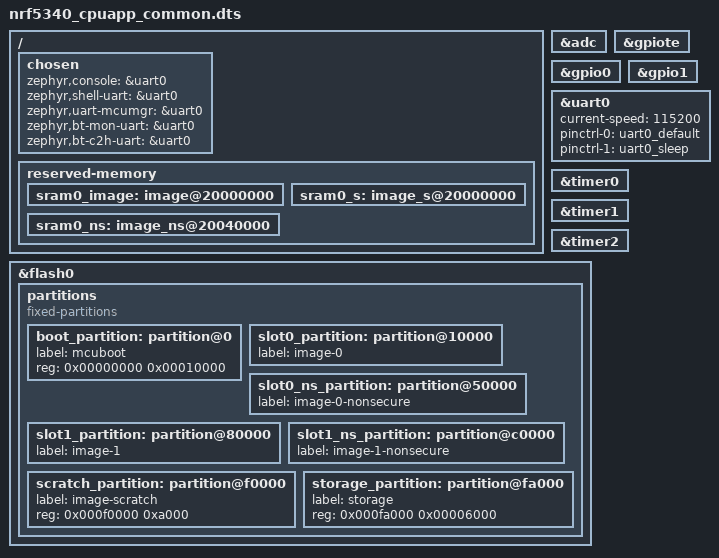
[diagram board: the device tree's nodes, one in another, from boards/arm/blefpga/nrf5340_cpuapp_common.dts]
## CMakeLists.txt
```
#
# Copyright (c) 2018 Nordic Semiconductor
#
# SPDX-License-Identifier: LicenseRef-Nordic-5-Clause
#
cmake_minimum_required(VERSION 3.20.0)

find_package(Zephyr REQUIRED HINTS $ENV{ZEPHYR_BASE})
project(peripheral_uart_app080724d)

# NORDIC SDK APP START
target_sources(app PRIVATE
  src/main.c
  src/utils.c
  src/spimflash.c
)

# Include UART ASYNC API adapter
target_sources_ifdef(CONFIG_BT_NUS_UART_ASYNC_ADAPTER app PRIVATE
  src/uart_async_adapter.c
)

# NORDIC SDK APP END

zephyr_library_include_directories(.)
```

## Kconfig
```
#
# Copyright (c) 2018 Nordic Semiconductor
#
# SPDX-License-Identifier: LicenseRef-Nordic-5-Clause
#

config USB_DEVICE_PID
	default USB_PID_CDC_ACM_SAMPLE

source "Kconfig.zephyr"

menu "Nordic UART BLE GATT service sample"

config BT_NUS_THREAD_STACK_SIZE
	int "Thread stack size"
	default 1024
	help
	  Stack size used in each of the two threads

config BT_NUS_UART_BUFFER_SIZE
	int "UART payload buffer element size"
	default 40
	help
	  Size of the payload buffer in each RX and TX FIFO element

config BT_NUS_SECURITY_ENABLED
	bool "Enable security"
	default y
	select BT_SMP
	help
	  "Enable BLE security for the UART service"

config BT_NUS_UART_RX_WAIT_TIME
	int "Timeout for UART RX complete event"
	default 50
	help
	  Wait for RX complete event time in milliseconds

config BT_NUS_UART_ASYNC_ADAPTER
	bool "Enable UART async adapter"
	select SERIAL_SUPPORT_ASYNC
	help
	  Enables asynchronous adapter for UART drives that supports only
	  IRQ interface.

endmenu
```

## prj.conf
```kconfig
#
# Copyright (c) 2018 Nordic Semiconductor
#
# SPDX-License-Identifier: LicenseRef-Nordic-5-Clause
#

# Enable the UART driver
CONFIG_UART_ASYNC_API=y
CONFIG_NRFX_UARTE0=y
CONFIG_SERIAL=y

CONFIG_GPIO=y

# Make sure printk is printing to the UART console
CONFIG_CONSOLE=y
CONFIG_UART_CONSOLE=y

CONFIG_HEAP_MEM_POOL_SIZE=2048

CONFIG_BT=y
CONFIG_BT_PERIPHERAL=y
CONFIG_BT_DEVICE_NAME="NRFICE"
CONFIG_BT_DEVICE_APPEARANCE=833
CONFIG_BT_MAX_CONN=1
CONFIG_BT_MAX_PAIRED=1

# Enable the NUS service
CONFIG_BT_NUS=y

# Enable bonding
CONFIG_BT_SETTINGS=y
CONFIG_FLASH=y
CONFIG_FLASH_PAGE_LAYOUT=y
CONFIG_FLASH_MAP=y
CONFIG_NVS=y
CONFIG_SETTINGS=y

# Enable DK LED and Buttons library
CONFIG_DK_LIBRARY=y

# This example requires more stack
CONFIG_MAIN_STACK_SIZE=1152
CONFIG_SYSTEM_WORKQUEUE_STACK_SIZE=2048

# Config logger
CONFIG_LOG=y
CONFIG_USE_SEGGER_RTT=y
CONFIG_LOG_BACKEND_RTT=y
CONFIG_LOG_BACKEND_UART=n
CONFIG_LOG_PRINTK=n

CONFIG_ASSERT=y





CONFIG_BT_USER_DATA_LEN_UPDATE=y
CONFIG_BT_USER_PHY_UPDATE=y
CONFIG_BT_GAP_AUTO_UPDATE_CONN_PARAMS=n

CONFIG_BT_BUF_ACL_RX_SIZE=251
CONFIG_BT_GATT_CLIENT=y
CONFIG_BT_ATT_PREPARE_COUNT=2
CONFIG_BT_CONN_TX_MAX=10
CONFIG_BT_L2CAP_TX_BUF_COUNT=10
CONFIG_BT_L2CAP_TX_MTU=247
CONFIG_BT_L2CAP_DYNAMIC_CHANNEL=y
CONFIG_BT_CTLR_PHY_2M=y
CONFIG_BT_CTLR_RX_BUFFERS=2
CONFIG_BT_BUF_ACL_TX_COUNT=10
CONFIG_BT_BUF_ACL_TX_SIZE=251
CONFIG_BT_CTLR_DATA_LENGTH_MAX=251
```

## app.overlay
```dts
/*
 * Copyright (c) 2022 Nordic Semiconductor ASA
 *
 * SPDX-License-Identifier: LicenseRef-Nordic-5-Clause
 */

/ {
	chosen {
		nordic,nus-uart = &uart0;
	};
};

&qspi {
	status = "disabled";
};

&adc {
	status = "disabled";
};
```

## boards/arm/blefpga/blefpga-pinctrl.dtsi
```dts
/*
 * Copyright (c) 2022 Nordic Semiconductor
 * SPDX-License-Identifier: Apache-2.0
 */

&pinctrl {
	/*spi2_default: spi2_default {
		group1 {
			psels = <NRF_PSEL(SPIM_SCK, 1, 15)>,
				<NRF_PSEL(SPIM_MISO, 1, 14)>,
				<NRF_PSEL(SPIM_MOSI, 1, 13)>;
		};
	};

	spi2_sleep: spi2_sleep {
		group1 {
			psels = <NRF_PSEL(SPIM_SCK, 1, 15)>,
				<NRF_PSEL(SPIM_MISO, 1, 14)>,
				<NRF_PSEL(SPIM_MOSI, 1, 13)>;
			low-power-enable;
		};
	};*/

};
```

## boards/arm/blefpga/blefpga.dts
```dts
/*
 * Copyright (c) 2020 Nordic Semiconductor ASA
 *
 * SPDX-License-Identifier: Apache-2.0
 */

/dts-v1/;
#include <nordic/nrf5340_cpuapp_qkaa.dtsi>
#include "nrf5340_cpuapp_common.dts"
#include "blefpga-pinctrl.dtsi"

/ {
	model = "BLEFPGA Application";
	compatible = "nordic,blefpga";

	chosen {
		zephyr,sram = &sram0_image;
		zephyr,flash = &flash0;
		zephyr,code-partition = &slot0_partition;
		zephyr,sram-secure-partition = &sram0_s;
		zephyr,sram-non-secure-partition = &sram0_ns;
	};
};

/*&spi2 {
	compatible = "nordic,nrf-spim";
	status = "okay";
	pinctrl-0 = <&spi2_default>;
	pinctrl-1 = <&spi2_sleep>;
	pinctrl-names = "default", "sleep";
};*/

zephyr_udc0: &usbd {
	compatible = "nordic,nrf-usbd";
	status = "okay";
};
```

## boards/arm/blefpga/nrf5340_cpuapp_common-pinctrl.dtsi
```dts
/*
 * Copyright (c) 2022 Nordic Semiconductor
 * SPDX-License-Identifier: Apache-2.0
 */

&pinctrl {
	/*i2c1_default: i2c1_default {
		group1 {
			psels = <NRF_PSEL(TWIM_SDA, 1, 2)>,
				<NRF_PSEL(TWIM_SCL, 1, 3)>;
		};
	};

	i2c1_sleep: i2c1_sleep {
		group1 {
			psels = <NRF_PSEL(TWIM_SDA, 1, 2)>,
				<NRF_PSEL(TWIM_SCL, 1, 3)>;
			low-power-enable;
		};
	};*/
	uart0_default: uart0_default {
		group1 {
			psels = <NRF_PSEL(UART_TX, 0, 22)>,   //orig: 20, pololu: 26
				<NRF_PSEL(UART_RTS, 0, 30)>;    //orig: 19, pololu: 27
		};
		group2 {
			psels = <NRF_PSEL(UART_RX, 0, 29)>,   //orig: 22, pololu: 6
				<NRF_PSEL(UART_CTS, 1, 7)>;   //orig: 21, pololu: 7
			bias-pull-up;
		};
		
	};

	uart0_sleep: uart0_sleep {
		group1 {
			psels = <NRF_PSEL(UART_TX, 0, 22)>,
				<NRF_PSEL(UART_RX, 0, 29)>,
				<NRF_PSEL(UART_RTS, 0, 30)>,
				<NRF_PSEL(UART_CTS, 1, 7)>;
			low-power-enable;
		};
	};
	/* should be good but not working through ob yet
	uart0_default: uart0_default {
		group1 {
			psels = <NRF_PSEL(UART_TX, 0, 29)>,   //orig: 20, pololu: 26
				<NRF_PSEL(UART_RTS, 0, 30)>;    //orig: 19, pololu: 27
		};
		group2 {
			psels = <NRF_PSEL(UART_RX, 0, 22)>,   //orig: 22, pololu: 6
				<NRF_PSEL(UART_CTS, 1, 7)>;   //orig: 21, pololu: 7
			bias-pull-up;
		};
		
	};

	uart0_sleep: uart0_sleep {
		group1 {
			psels = <NRF_PSEL(UART_TX, 0, 29)>,
				<NRF_PSEL(UART_RX, 0, 22)>,
				<NRF_PSEL(UART_RTS, 0, 30)>,
				<NRF_PSEL(UART_CTS, 1, 7)>;
			low-power-enable;
		};
	};*/

	/*pwm0_default: pwm0_default {
		group1 {
			psels = <NRF_PSEL(PWM_OUT0, 0, 28)>;
		};
	};

	pwm0_sleep: pwm0_sleep {
		group1 {
			psels = <NRF_PSEL(PWM_OUT0, 0, 28)>;
			low-power-enable;
		};
	};*/

	/*qspi_default: qspi_default {
		group1 {
			psels = <NRF_PSEL(QSPI_SCK, 0, 17)>,
				<NRF_PSEL(QSPI_IO0, 0, 13)>,
				<NRF_PSEL(QSPI_IO1, 0, 14)>,
				<NRF_PSEL(QSPI_IO2, 0, 15)>,
				<NRF_PSEL(QSPI_IO3, 0, 16)>,
				<NRF_PSEL(QSPI_CSN, 0, 18)>;
		};
	};

	qspi_sleep: qspi_sleep {
		group1 {
			psels = <NRF_PSEL(QSPI_SCK, 0, 17)>,
				<NRF_PSEL(QSPI_IO0, 0, 13)>,
				<NRF_PSEL(QSPI_IO1, 0, 14)>,
				<NRF_PSEL(QSPI_IO2, 0, 15)>,
				<NRF_PSEL(QSPI_IO3, 0, 16)>,
				<NRF_PSEL(QSPI_CSN, 0, 18)>;
			low-power-enable;
		};
	};*/

	/*uart1_default: uart1_default {
		group1 {
			psels = <NRF_PSEL(UART_TX, 1, 1)>;
		};
		group2 {
			psels = <NRF_PSEL(UART_RX, 1, 0)>;
			bias-pull-up;
		};
	};

	uart1_sleep: uart1_sleep {
		group1 {
			psels = <NRF_PSEL(UART_TX, 1, 1)>,
				<NRF_PSEL(UART_RX, 1, 0)>;
			low-power-enable;
		};
	};*/

	/*spi4_default: spi4_default {
		group1 {
			psels = <NRF_PSEL(SPIM_SCK, 1, 15)>,
				<NRF_PSEL(SPIM_MISO, 1, 14)>,
				<NRF_PSEL(SPIM_MOSI, 1, 13)>;
		};
	};

	spi4_sleep: spi4_sleep {
		group1 {
			psels = <NRF_PSEL(SPIM_SCK, 1, 15)>,
				<NRF_PSEL(SPIM_MISO, 1, 14)>,
				<NRF_PSEL(SPIM_MOSI, 1, 13)>;
			low-power-enable;
		};
	};*/

};
```

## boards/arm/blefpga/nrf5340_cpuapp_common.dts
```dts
/*
 * Copyright (c) 2019-2020 Nordic Semiconductor ASA
 *
 * SPDX-License-Identifier: Apache-2.0
 */
#include "nrf5340_cpuapp_common-pinctrl.dtsi"

/ {

	chosen {
		zephyr,console = &uart0;
		zephyr,shell-uart = &uart0;
		zephyr,uart-mcumgr = &uart0;
		zephyr,bt-mon-uart = &uart0;
		zephyr,bt-c2h-uart = &uart0;
	};

 	/*leds {
		compatible = "gpio-leds";
		led0: led_0 {
			gpios = <&gpio1 4 GPIO_ACTIVE_LOW>;
			label = "Green LED 0";
		};
		led1: led_1 {
			gpios = <&gpio1 5 GPIO_ACTIVE_LOW>;
			label = "Green LED 1";
		};
		led2: led_2 {
			gpios = <&gpio0 19 GPIO_ACTIVE_LOW>;
			label = "Green LED 2";
		};
		led3: led_3 {
			gpios = <&gpio0 29 GPIO_ACTIVE_LOW>;
			label = "Green LED 3";
		};
	};*/

	/*pwmleds {
		compatible = "pwm-leds";
		pwm_led0: pwm_led_0 {
			pwms = <&pwm0 0 PWM_MSEC(20) PWM_POLARITY_INVERTED>;
		};
	};*/

	/*buttons {
		compatible = "gpio-keys";
		button0: button_0 {
			gpios = <&gpio0 23 (GPIO_PULL_UP | GPIO_ACTIVE_LOW)>; //dk:23
			label = "Push button 1";
		};
		button1: button_1 {
			gpios = <&gpio0 24 (GPIO_PULL_UP | GPIO_ACTIVE_LOW)>;
			label = "Push button 2";
		};
		button2: button_2 {
			gpios = <&gpio0 8 (GPIO_PULL_UP | GPIO_ACTIVE_LOW)>;
			label = "Push button 3";
		};
		button3: button_3 {
			gpios = <&gpio0 9 (GPIO_PULL_UP | GPIO_ACTIVE_LOW)>;
			label = "Push button 4";
		};
	};*/

	// arduino_header: connector {
	// 	compatible = "arduino-header-r3";
	// 	#gpio-cells = <2>;
	// 	gpio-map-mask = <0xffffffff 0xffffffc0>;
	// 	gpio-map-pass-thru = <0 0x3f>;
	// 	gpio-map = <0 0 &gpio0 4 0>,	/* A0 */
	// 		   <1 0 &gpio0 5 0>,	/* A1 */
	// 		   <2 0 &gpio0 6 0>,	/* A2 */
	// 		   <3 0 &gpio0 7 0>,	/* A3 */
	// 		   <4 0 &gpio0 25 0>,	/* A4 */
	// 		   <5 0 &gpio0 26 0>,	/* A5 */
	// 		   <6 0 &gpio1 0 0>,	/* D0 */
	// 		   <7 0 &gpio1 1 0>,	/* D1 */
	// 		   <8 0 &gpio1 4 0>,	/* D2 */
	// 		   <9 0 &gpio1 5 0>,	/* D3 */
	// 		   <10 0 &gpio1 6 0>,	/* D4 */
	// 		   <11 0 &gpio1 7 0>,	/* D5 */
	// 		   <12 0 &gpio1 8 0>,	/* D6 */
	// 		   <13 0 &gpio1 9 0>,	/* D7 */
	// 		   <14 0 &gpio1 10 0>,	/* D8 */
	// 		   <15 0 &gpio1 11 0>,	/* D9 */
	// 		   <16 0 &gpio1 12 0>,	/* D10 */
	// 		   <17 0 &gpio1 13 0>,	/* D11 */
	// 		   <18 0 &gpio1 14 0>,	/* D12 */
	// 		   <19 0 &gpio1 15 0>,	/* D13 */
	// 		   <20 0 &gpio1 2 0>,	/* D14 */
	// 		   <21 0 &gpio1 3 0>;	/* D15 */
	// };

 	// arduino_adc: analog-connector {
	// 	compatible = "arduino,uno-adc";
	// 	#io-channel-cells = <1>;
	// 	io-channel-map = <0 &adc 0>,	/* A0 = P0.4 = AIN0 */
	// 			 <1 &adc 1>,	/* A1 = P0.5 = AIN1 */
	// 			 <2 &adc 2>,	/* A2 = P0.6 = AIN2 */
	// 			 <3 &adc 3>,	/* A3 = P0.7 = AIN3 */
	// 			 <4 &adc 4>,	/* A4 = P0.25 = AIN4 */
	// 			 <5 &adc 5>;	/* A5 = P0.26 = AIN5 */
	// };

	/*gpio_fwd: nrf-gpio-forwarder {
		compatible = "nordic,nrf-gpio-forwarder";
		status = "okay";
		uart {
			gpios = <&gpio1 1 0>, <&gpio1 0 0>, <&gpio0 11 0>, <&gpio0 10 0>;
		};
	};*/

	/* These aliases are provided for compatibility with samples */
	/*aliases {
		led0 = &led0;
		led1 = &led1;
		led2 = &led2;
		// led3 = &led3;
		//pwm-led0 = &pwm_led0;
		sw0 = &button0;
		sw1 = &button1;
		sw2 = &button2;
		sw3 = &button3;
		bootloader-led0 = &led0;
	};*/
};

&adc {
	status = "okay";
};

&gpiote {
	status = "okay";
};

&gpio0 {
	status = "okay";
};

&gpio1 {
	status = "okay";
};

/*&i2c1 {
	compatible = "nordic,nrf-twim";
	status = "okay";
	pinctrl-0 = <&i2c1_default>;
	pinctrl-1 = <&i2c1_sleep>;
	pinctrl-names = "default", "sleep";
};*/

&uart0 {
	status = "okay";
	current-speed = <115200>;
	pinctrl-0 = <&uart0_default>;
	pinctrl-1 = <&uart0_sleep>;
	pinctrl-names = "default", "sleep";
	//hw-flow-control;
};

/*&pwm0 {
	status = "okay";
	pinctrl-0 = <&pwm0_default>;
	pinctrl-1 = <&pwm0_sleep>;
	pinctrl-names = "default", "sleep";
};*/

/*&qspi {
	status = "okay";
	pinctrl-0 = <&qspi_default>;
	pinctrl-1 = <&qspi_sleep>;
	pinctrl-names = "default", "sleep";
	mx25r64: mx25r6435f@0 {
		compatible = "nordic,qspi-nor";
		reg = <0>;
		
		writeoc = "pp4io";
		
		readoc = "read4io";
		sck-frequency = <8000000>;
		label = "MX25R64";
		jedec-id = [c2 28 17];
		sfdp-bfp = [
			e5 20 f1 ff  ff ff ff 03  44 eb 08 6b  08 3b 04 bb
			ee ff ff ff  ff ff 00 ff  ff ff 00 ff  0c 20 0f 52
			10 d8 00 ff  23 72 f5 00  82 ed 04 cc  44 83 68 44
			30 b0 30 b0  f7 c4 d5 5c  00 be 29 ff  f0 d0 ff ff
		];
		size = <67108864>;
		has-dpd;
		t-enter-dpd = <10000>;
		t-exit-dpd = <35000>;
	};
};*/

&timer0 {
	status = "okay";
};

&timer1 {
	status = "okay";
};

&timer2 {
	status = "okay";
};

/*arduino_serial: &uart1 {
	compatible = "nordic,nrf-uarte";
	current-speed = <115200>;
	pinctrl-0 = <&uart1_default>;
	pinctrl-1 = <&uart1_sleep>;
	pinctrl-names = "default", "sleep";
};*/

/*arduino_i2c: &i2c1 {};

arduino_spi: &spi4 {
	compatible = "nordic,nrf-spim";
	cs-gpios = <&arduino_header 16 GPIO_ACTIVE_LOW>; 
	pinctrl-0 = <&spi4_default>;
	pinctrl-1 = <&spi4_sleep>;
	pinctrl-names = "default", "sleep";
};*/

&flash0 {

	partitions {
		compatible = "fixed-partitions";
		#address-cells = <1>;
		#size-cells = <1>;

		boot_partition: partition@0 {
			label = "mcuboot";
			reg = <0x00000000 0x00010000>;
		};
		slot0_partition: partition@10000 {
			label = "image-0";
		};
		slot0_ns_partition: partition@50000 {
			label = "image-0-nonsecure";
		};
		slot1_partition: partition@80000 {
			label = "image-1";
		};
		slot1_ns_partition: partition@c0000 {
			label = "image-1-nonsecure";
		};
		scratch_partition: partition@f0000 {
			label = "image-scratch";
			reg = <0x000f0000 0xa000>;
		};
		storage_partition: partition@fa000 {
			label = "storage";
			reg = <0x000fa000 0x00006000>;
		};
	};
};

/ {

	reserved-memory {
		#address-cells = <1>;
		#size-cells = <1>;
		ranges;

		sram0_image: image@20000000 {
			/* Zephyr image(s) memory */
		};

		sram0_s: image_s@20000000 {
			/* Secure image memory */
		};

		sram0_ns: image_ns@20040000 {
			/* Non-Secure image memory */
		};
	};
};

/* Include partition configuration file */
#include "nrf5340_cpuapp_partition_conf.dts"
```

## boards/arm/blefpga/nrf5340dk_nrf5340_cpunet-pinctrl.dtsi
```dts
/*
 * Copyright (c) 2022 Nordic Semiconductor
 * SPDX-License-Identifier: Apache-2.0
 */

&pinctrl {
 	uart0_default: uart0_default {
		group1 {
			psels = <NRF_PSEL(UART_TX, 1, 1)>,
				<NRF_PSEL(UART_RTS, 0, 11)>;
		};
		group2 {
			psels = <NRF_PSEL(UART_RX, 1, 0)>,
				<NRF_PSEL(UART_CTS, 0, 10)>;
			bias-pull-up;
		};
	};

	uart0_sleep: uart0_sleep {
		group1 {
			psels = <NRF_PSEL(UART_TX, 1, 1)>,
				<NRF_PSEL(UART_RX, 1, 0)>,
				<NRF_PSEL(UART_RTS, 0, 11)>,
				<NRF_PSEL(UART_CTS, 0, 10)>;
			low-power-enable;
		};
	};

/* 	i2c0_default: i2c0_default {
		group1 {
			psels = <NRF_PSEL(TWIM_SDA, 1, 2)>,
				<NRF_PSEL(TWIM_SCL, 1, 3)>;
		};
	};

	i2c0_sleep: i2c0_sleep {
		group1 {
			psels = <NRF_PSEL(TWIM_SDA, 1, 2)>,
				<NRF_PSEL(TWIM_SCL, 1, 3)>;
			low-power-enable;
		};
	};

	spi0_default: spi0_default {
		group1 {
			psels = <NRF_PSEL(SPIM_SCK, 1, 15)>,
				<NRF_PSEL(SPIM_MISO, 1, 14)>,
				<NRF_PSEL(SPIM_MOSI, 1, 13)>;
		};
	};

	spi0_sleep: spi0_sleep {
		group1 {
			psels = <NRF_PSEL(SPIM_SCK, 1, 15)>,
				<NRF_PSEL(SPIM_MISO, 1, 14)>,
				<NRF_PSEL(SPIM_MOSI, 1, 13)>;
			low-power-enable;
		};
	};*/

};
```

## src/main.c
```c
/*
MIT License

Copyright (c) 2024 Hurley Research LLC

Permission is hereby granted, free of charge, to any person obtaining a copy
of this software and associated documentation files (the "Software"), to deal
in the Software without restriction, including without limitation the rights
to use, copy, modify, merge, publish, distribute, sublicense, and/or sell
copies of the Software, and to permit persons to whom the Software is
furnished to do so, subject to the following conditions:

The above copyright notice and this permission notice shall be included in all
copies or substantial portions of the Software.

THE SOFTWARE IS PROVIDED "AS IS", WITHOUT WARRANTY OF ANY KIND, EXPRESS OR
IMPLIED, INCLUDING BUT NOT LIMITED TO THE WARRANTIES OF MERCHANTABILITY,
FITNESS FOR A PARTICULAR PURPOSE AND NONINFRINGEMENT. IN NO EVENT SHALL THE
AUTHORS OR COPYRIGHT HOLDERS BE LIABLE FOR ANY CLAIM, DAMAGES OR OTHER
LIABILITY, WHETHER IN AN ACTION OF CONTRACT, TORT OR OTHERWISE, ARISING FROM,
OUT OF OR IN CONNECTION WITH THE SOFTWARE OR THE USE OR OTHER DEALINGS IN THE
SOFTWARE.
 */

/** @file
 *  @brief Nordic UART Bridge Service (NUS) sample
 */
#include "uart_async_adapter.h"

#include <zephyr/types.h>
#include <zephyr/kernel.h>
#include <zephyr/drivers/uart.h>
#include <zephyr/usb/usb_device.h>

#include <zephyr/device.h>
#include <zephyr/devicetree.h>
#include <soc.h>

#include <zephyr/bluetooth/bluetooth.h>
#include <zephyr/bluetooth/uuid.h>
#include <zephyr/bluetooth/gatt.h>
#include <zephyr/bluetooth/hci.h>

#include <bluetooth/services/nus.h>

#include <dk_buttons_and_leds.h>

#include <zephyr/settings/settings.h>

#include <stdio.h>

#include <zephyr/logging/log.h>

#include "spimflash.h"
#include "utils.h"
#define testdelay k_sleep(K_MSEC(1))
#define LOG_MODULE_NAME peripheral_uart
LOG_MODULE_REGISTER(LOG_MODULE_NAME);

#define STACKSIZE CONFIG_BT_NUS_THREAD_STACK_SIZE
#define PRIORITY 7

#define DEVICE_NAME CONFIG_BT_DEVICE_NAME
#define DEVICE_NAME_LEN (sizeof(DEVICE_NAME) - 1)

static K_SEM_DEFINE(ble_init_ok, 0, 1);

static struct bt_conn *current_conn;
static struct bt_conn *auth_conn;

static const struct bt_data ad[] = {
	BT_DATA_BYTES(BT_DATA_FLAGS, (BT_LE_AD_GENERAL | BT_LE_AD_NO_BREDR)),
	BT_DATA(BT_DATA_NAME_COMPLETE, DEVICE_NAME, DEVICE_NAME_LEN),
};

static const struct bt_data sd[] = {
	BT_DATA_BYTES(BT_DATA_UUID128_ALL, BT_UUID_NUS_VAL),
};

#if CONFIG_BT_NUS_UART_ASYNC_ADAPTER
UART_ASYNC_ADAPTER_INST_DEFINE(async_adapter);
#else
// static const struct device *const async_adapter;
#endif


#define NCOMMANDS 10

#define COMMAND_READ_FLASH_BT 110
#define COMMAND_READ_FLASH_STATUS 111
#define COMMAND_WRITE_FLASH 112
#define COMMAND_ERASE_FLASH 113
#define COMMAND_TEST_FLASH 114
#define COMMAND_HARDRESETICE 115
#define COMMAND_SOFTRESETEICE 116
#define COMMAND_CRESETBLOW 117
#define COMMAND_CRESETBHIGH 118
#define COMMAND_TESTREADFLASH 119
#define COMMAND_TESTWRITEFLASH 127
#define COMMAND_ERASEZERO 131

#define COMMAND_TESTBTSEND 132

#define COMMAND_READ_FLASH_SERIAL 120
#define COMMAND_RAMTEST 121
#define COMMAND_RAMTESTLONG 122

#define COMMAND_SETRGB 210
#define COMMANDLENGTH 128
uint8_t commandBytes[COMMANDLENGTH];

static void connected(struct bt_conn *conn, uint8_t err)
{
	char addr[BT_ADDR_LE_STR_LEN];
	if (err)
	{
		lg("connection failed\n");
		LOG_ERR("Connection failed (err %u)", err);
		return;
	}
	bt_addr_le_to_str(bt_conn_get_dst(conn), addr, sizeof(addr));

	current_conn = bt_conn_ref(conn);

    struct bt_conn_info info;
	bt_conn_get_info(current_conn,&info);
	lgv("set conn val %i\n",info.id);

}

static void disconnected(struct bt_conn *conn, uint8_t reason)
{
	char addr[BT_ADDR_LE_STR_LEN];
	lg("disconnected\n");
	bt_addr_le_to_str(bt_conn_get_dst(conn), addr, sizeof(addr));
	LOG_INF("Disconnected: %s (reason %u)", addr, reason);
	if (auth_conn)
	{
		bt_conn_unref(auth_conn);
		auth_conn = NULL;
	}
	if (current_conn)
	{
		bt_conn_unref(current_conn);
		current_conn = NULL;
	}
}

#ifdef CONFIG_BT_NUS_SECURITY_ENABLED
static void security_changed(struct bt_conn *conn, bt_security_t level,
							 enum bt_security_err err)
{
	char addr[BT_ADDR_LE_STR_LEN];
	bt_addr_le_to_str(bt_conn_get_dst(conn), addr, sizeof(addr));
	if (!err)
	{
		LOG_INF("Security changed: %s level %u", addr, level);
	}
	else
	{
		LOG_WRN("Security failed: %s level %u err %d", addr,
				level, err);
	}
}
#endif

BT_CONN_CB_DEFINE(conn_callbacks) = {
	.connected = connected,
	.disconnected = disconnected,
#ifdef CONFIG_BT_NUS_SECURITY_ENABLED
	.security_changed = security_changed,
#endif
};

#if defined(CONFIG_BT_NUS_SECURITY_ENABLED)
static void auth_passkey_display(struct bt_conn *conn, unsigned int passkey)
{
	char addr[BT_ADDR_LE_STR_LEN];
	bt_addr_le_to_str(bt_conn_get_dst(conn), addr, sizeof(addr));
	LOG_INF("Passkey for %s: %06u", addr, passkey);
}

static void auth_passkey_confirm(struct bt_conn *conn, unsigned int passkey)
{
	char addr[BT_ADDR_LE_STR_LEN];
	auth_conn = bt_conn_ref(conn);
	bt_addr_le_to_str(bt_conn_get_dst(conn), addr, sizeof(addr));
	LOG_INF("Passkey for %s: %06u", addr, passkey);
	LOG_INF("Press Button 1 to confirm, Button 2 to reject.");
}

static void auth_cancel(struct bt_conn *conn)
{
	char addr[BT_ADDR_LE_STR_LEN];
	bt_addr_le_to_str(bt_conn_get_dst(conn), addr, sizeof(addr));
	LOG_INF("Pairing cancelled: %s", addr);
}

static void pairing_complete(struct bt_conn *conn, bool bonded)
{
	char addr[BT_ADDR_LE_STR_LEN];
	bt_addr_le_to_str(bt_conn_get_dst(conn), addr, sizeof(addr));
	LOG_INF("Pairing completed: %s, bonded: %d", addr, bonded);
}

static void pairing_failed(struct bt_conn *conn, enum bt_security_err reason)
{
	char addr[BT_ADDR_LE_STR_LEN];
	bt_addr_le_to_str(bt_conn_get_dst(conn), addr, sizeof(addr));
	LOG_INF("Pairing failed conn: %s, reason %d", addr, reason);
}

static struct bt_conn_auth_cb conn_auth_callbacks = {
	.passkey_display = auth_passkey_display,
	.passkey_confirm = auth_passkey_confirm,
	.cancel = auth_cancel,
};

static struct bt_conn_auth_info_cb conn_auth_info_callbacks = {
	.pairing_complete = pairing_complete,
	.pairing_failed = pairing_failed};
#else
static struct bt_conn_auth_cb conn_auth_callbacks;
static struct bt_conn_auth_info_cb conn_auth_info_callbacks;
#endif

///////////////////////////////////////////////////////////////////////////////////////////////////
////////////////////////////////////////////////////////////////////////////////////////////////////








uint8_t flashTestBuf[128];
uint8_t readBufBT[20];
uint8_t sendBufBT[20];

uint32_t waitCount = 0;

uint32_t flashReadStartAddress = 0;
uint32_t flashReadLength = 0;
uint32_t flashReadCurrentAddress = 0;
uint32_t flashReadSessionID = 0;
void flashGPIOICE()
{
	gpioConfigInputNoPull(ICE_SCK); 
	gpioConfigInputNoPull(ICE_SSB); 
									
	gpioConfigInputNoPull(ICE_SDI);
	gpioConfigInputNoPull(ICE_SDO);
}

void flashGPIONRF()
{
	gpioConfigOutputDrive(ICE_SCK, DRIVEH0H1); 
	pinClear(ICE_SSB);
	gpioConfigOutputDrive(ICE_SSB, DRIVEH0H1);
	pinSet(ICE_SSB);

	gpioConfigOutputDrive(ICE_SDI, DRIVEH0H1);
	pinClear(ICE_SDI);

	gpioConfigInputNoPull(ICE_SDO);
}

void commandReadFlashBT(uint8_t *data)
{
	pinClear(ICE_CRESETB);
	flashReadStartAddress = unpack32(data, 4);
	flashReadLength = unpack32(data, 8);
	flashReadSessionID = unpack32(data, 12);
	flashReadCurrentAddress = flashReadStartAddress;
	lgv("readFlashBT %d\n", flashReadSessionID);
}
char hexChars[] = {
	'0',
	'1',
	'2',
	'3',
	'4',
	'5',
	'6',
	'7',
	'8',
	'9',
	'A',
	'B',
	'C',
	'D',
	'E',
	'F',
};
void bytesToHexString(uint8_t *bytes, char *str, int len)
{
	for (int i = 0; i < len; i++)
	{
		uint8_t b = bytes[i];
		str[i * 2] = hexChars[(b >> 4) & 0x0f];
		str[i * 2 + 1] = hexChars[b & 0x0f];
	}
}
void commandReadFlashStatus()
{
	pinClear(ICE_CRESETB);

	uint8_t status = flashReadStatus();
	lgv("yayflash status %d\n", status);

}
uint32_t maxWaitCount = 0;
uint8_t readCheckBuf[16];
void commandWriteFlash(uint8_t *data, uint8_t len)
{
	pinClear(ICE_CRESETB);

	uint8_t status = flashReadStatus();

	uint32_t startAddress = unpack24(data, 1);

	if (startAddress % 0x1000 == 0)
	{
	}

	flashWriteEnable();
	flashProgram(data, startAddress, len);

	waitCount = 0;
	status = flashReadStatus();
	while (status > 0)
	{
		status = flashReadStatus();
		waitCount++;
	}
	if (waitCount > maxWaitCount)
	{
		maxWaitCount = waitCount;
	}

	flashWriteDisable();
	flashRead(readCheckBuf, startAddress, len);
	uint32_t badX = 0;
	uint8_t allGood = 1;
	for (uint8_t x = 0; x < len; x++)
	{
		if (readCheckBuf[x] != data[x + 4])
		{
			allGood = 0;
			badX = x;
			x = len;
		}
	}
	if (allGood == 0)
	{

		lgv("allgood zero: \n", badX);

		flashWriteEnable();
		flashProgram(data, startAddress, len);

		flashWriteDisable();
		flashRead(readCheckBuf, startAddress, len);

		uint8_t allGoodAgain = 1;
		for (uint8_t x = 0; x < len; x++)
		{
			if (readCheckBuf[x] != data[x + 4])
			{
				allGoodAgain = 0;
				badX = x;
				x = len;
			}
		}
		if (allGoodAgain == 0)
		{

			lgv("allgood zero again: %d\n", badX);
		}
	}

	status = flashReadStatus();
	if (startAddress % 0x1000 == 0)
	{
	}
}

void commandEraseFlash(uint8_t *data)
{
	pinClear(ICE_CRESETB);

	uint32_t addr = unpack24(data, 1);

	uint8_t status = flashReadStatus();
	lgv("erase %d", status);
	waitCount = 0;
	flashWriteEnable();
	flashEraseSector(addr);

	status = flashReadStatus();

}

void commandEraseZero()
{
	pinClear(ICE_CRESETB);

	flashWriteEnable();
	flashEraseSector(0);
}

uint32_t insideFlashReadSession = 0;
void flashReadSession()
{

	insideFlashReadSession = 1;
	if (flashReadCurrentAddress < flashReadLength + flashReadStartAddress)
	{
		lg("readFlashSession");
		uint8_t status = flashReadStatus();
		if (status != 0)
		{

			lgv("abort %d\n", status);
			flashReadCurrentAddress = flashReadLength + flashReadStartAddress;
			insideFlashReadSession = 0;
			return;
		}
		flashRead(readBufBT, flashReadCurrentAddress, 16);
		for (uint8_t x = 0; x < 16; x++)
		{
			sendBufBT[x + 4] = readBufBT[x];
		}
		sendBufBT[0] = COMMAND_READ_FLASH_BT;
		pack24(flashReadCurrentAddress, sendBufBT, 1);

		int wth = bt_nus_send(current_conn, sendBufBT, 20);
		if (wth != 0)
		{
			lgv("prblm session %i\n", wth);
			flashReadCurrentAddress = flashReadLength + flashReadStartAddress;
		}
		else
		{
			flashReadCurrentAddress += 16;
		}
	}
	insideFlashReadSession = 0;
}

void testFlashRead(void)
{

	lg("testFlashRead");
	uint8_t status = flashReadStatus();
	lgv("test status read: %i\n", status);

	flashRead(readBufBT, 0, 16);
	for (uint8_t x = 0; x < 16; x++)
	{
		testdelay;
		lgv("readbuf %i\n", readBufBT[x]);
	}
}

void testBTSend(void)
{


	struct bt_conn_info info;
	bt_conn_get_info(current_conn,&info);
	lgv("sendID %i\n", info.id);

	for (uint8_t x = 0; x < 20; x++)
	{
		sendBufBT[x] = x;
	}
	sendBufBT[0] = COMMAND_READ_FLASH_BT;

	int wth = bt_nus_send(current_conn, sendBufBT, 20);

	if (wth != 0)
	{
		lgv("fprobnus %i\n", wth);
	}
	else
	{
		lgv("good nus %i\n", wth);
	}
}

void testFlashWrite(void)
{

	lg("testFlashWrite");
	uint8_t status = flashReadStatus();
	lgv("testFlashWrite: %i\n", status);
	for (int x = 0; x < 64; x++)
	{
		flashTestBuf[x] = x;
		flashWriteEnable();
	}
	flashProgram(flashTestBuf, 0, 64);
	lg("after flash program");
}

#define testdelay k_sleep(K_MSEC(1))
void writeEBRByte(uint8_t byte) {
    for (uint8_t b = 0; b < 8; b++) {
        if (((byte >> (7 - b)) & 0x01) == 0x01) {
            pinSet(ICEAPP_SPIMOSI);
        } else {
            pinClear(ICEAPP_SPIMOSI);
        }
        testdelay;
        pinSet(ICEAPP_SPICLK);
        testdelay;
        pinClear(ICEAPP_SPICLK);
    }
}
void writeEBR(uint8_t addr, uint16_t val)
{
	testdelay;
	pinClear(ICEAPP_SPICLK);
	pinClear(ICEAPP_SPIMOSI);
	pinClear(ICEAPP_SPICSN);
	testdelay;
	writeEBRByte(0x10); 
	testdelay;
	writeEBRByte(addr);
	testdelay;
	writeEBRByte((val >> 8) & 0xff);
	testdelay;
	writeEBRByte(val & 0xff);
	testdelay;

	pinSet(ICEAPP_SPICSN);
	pinClear(ICEAPP_SPICLK);
	pinClear(ICEAPP_SPIMOSI);
}


void writeFPGARGB(uint8_t addr, uint8_t val)
{
	testdelay;
	pinClear(ICEAPP_SPICLK);
	pinClear(ICEAPP_SPIMOSI);
	pinClear(ICEAPP_SPICSN);
	testdelay;
	writeEBRByte(0x12 + addr); 
	testdelay;
	writeEBRByte(addr);
	testdelay;
	writeEBRByte(0);
	testdelay;
	writeEBRByte(val & 0xff);
	testdelay;

	pinSet(ICEAPP_SPICSN);
	pinClear(ICEAPP_SPICLK);
	pinClear(ICEAPP_SPIMOSI);
	testdelay;
}



void setRGB(uint8_t *data) {
    uint8_t r = data[1];
    uint8_t g = data[2];
    uint8_t b = data[3];

    writeFPGARGB(0,r);
    writeFPGARGB(1,g);
    writeFPGARGB(2,b);


}


void processCommand(uint8_t payloadSize)
{

	uint8_t command = commandBytes[0];
      lgv("cmd %i\n", command);
	if (command == COMMAND_READ_FLASH_BT)
	{
		commandReadFlashBT(commandBytes);
	}
	else if (command == COMMAND_READ_FLASH_STATUS)
	{

		commandReadFlashStatus();
	}
	else if (command == COMMAND_READ_FLASH_SERIAL)
	{
		// commandReadFlashSerial(commandBytes);
	}
	else if (command == COMMAND_ERASEZERO)
	{
		commandEraseZero();
	}
	else if (command == COMMAND_RAMTEST)
	{
		// uint8_t ramAddr = commandBytes[1];
		// uint16_t ramData = unpack16(commandBytes, 2);
		// commandRamTest(ramAddr, ramData);
	}
	else if (command == COMMAND_RAMTESTLONG)
	{
		// commandRamTestLong();
	}
	else if (command == COMMAND_WRITE_FLASH)
	{
		commandWriteFlash(commandBytes, payloadSize);
	}
	else if (command == COMMAND_ERASE_FLASH)
	{
		commandEraseFlash(commandBytes);
	}
	else if (command == COMMAND_TEST_FLASH)
	{
		pinClear(ICE_CRESETB);
		uint8_t status = flashReadStatus();
		flashWriteEnable();
		status = flashReadStatus();
		flashWriteDisable();
		status = flashReadStatus();
	}
	else if (command == COMMAND_HARDRESETICE)
	{
		pinClear(NRF_LEDR);
		flashGPIOICE();
		k_sleep(K_MSEC(100));
		pinSet(ICE_CRESETB);
		k_sleep(K_MSEC(100));
		pinClear(ICE_CRESETB);
		k_sleep(K_MSEC(100));
		pinSet(ICE_CRESETB);
		pinSet(NRF_LEDR);
	
	}
	else if (command == COMMAND_SOFTRESETEICE)
	{

	


		pinClear(NRF_LEDG);
		pinClear(ICESOFTRESET);
		k_sleep(K_MSEC(100));
		pinSet(ICESOFTRESET);

		k_sleep(K_MSEC(100));
		pinClear(ICESOFTRESET);
		pinSet(NRF_LEDG);
	}
	else if (command == COMMAND_CRESETBLOW)
	{
		pinClear(ICE_CRESETB);
	}
	else if (command == COMMAND_CRESETBHIGH)
	{
		pinSet(ICE_CRESETB);
	}
	else if (command == COMMAND_TESTBTSEND)
	{
		testBTSend();
	}
	else if (command == COMMAND_TESTREADFLASH)
	{

		testFlashRead();

	}
	else if (command == COMMAND_TESTWRITEFLASH)
	{

		testFlashWrite();

	}
	else if (command == COMMAND_SETRGB)
	{
		setRGB(commandBytes);
	}
}
////////////////////////////////////////////////////////////

static void bt_receive_cb(struct bt_conn *conn, const uint8_t *const data, uint16_t len)
{

	char addr[BT_ADDR_LE_STR_LEN] = {0};



	bt_addr_le_to_str(bt_conn_get_dst(conn), addr, ARRAY_SIZE(addr));
	for (uint8_t x = 0; x < 20; x++)
	{
		commandBytes[x] = data[x];
	}
	processCommand(16);

}

static struct bt_nus_cb nus_cb = {
	.received = bt_receive_cb,
};

void error(void)
{
	while (true)
	{
		k_sleep(K_MSEC(1000));
	}
}

uint32_t hbi = 0;
void heartBeat(void)
{
	if (hbi % 2 == 0)
	{
		pinClear(NRF_LEDR);
	}
	else
	{
		pinSet(NRF_LEDR);
	}
	hbi++;

	if (insideFlashReadSession == 0)
	{
		flashReadSession();
	}
}

int main(void)
{
	
	int err = 0;

	gpioConfigOutputSet(ICEAPP_SPICSN);
	gpioConfigOutputClear(ICEAPP_SPICLK);
	gpioConfigOutputClear(ICEAPP_SPIMOSI);
	gpioConfigInputNoPull(ICEAPP_SPIMISO);
	gpioConfigOutputClear(ICESOFTRESET);
	gpioConfigOutputClear(ICE_CRESETB);

	gpioConfigOutputSet(NRF_LEDR);
	gpioConfigOutputSet(NRF_LEDG);
	gpioConfigOutputSet(NRF_LEDB);
	setupSeggerUART();
	lg("top of main");
	if (IS_ENABLED(CONFIG_BT_NUS_SECURITY_ENABLED))
	{
		err = bt_conn_auth_cb_register(&conn_auth_callbacks);
		if (err)
		{
			printk("Failed to register authorization callbacks.\n");
			return 0;
		}

		err = bt_conn_auth_info_cb_register(&conn_auth_info_callbacks);
		if (err)
		{
			printk("Failed to register authorization info callbacks.\n");
			return 0;
		}
	}
	err = bt_enable(NULL);
	if (err)
	{
		error();
	}
	LOG_INF("Bluetooth initialized");
	k_sem_give(&ble_init_ok);
	if (IS_ENABLED(CONFIG_SETTINGS))
	{
		settings_load();
	}
	err = bt_nus_init(&nus_cb);
	if (err)
	{
		LOG_ERR("Failed to initialize UART service (err: %d)", err);
		return 0;
	}
	err = bt_le_adv_start(BT_LE_ADV_CONN, ad, ARRAY_SIZE(ad), sd, ARRAY_SIZE(sd));
	if (err)
	{
		LOG_ERR("Advertising failed to start (err %d)", err);
		return 0;
	}
	spimFlashInit();

	for (;;)
	{

		k_sleep(K_MSEC(100));
		heartBeat();
	}
}
```

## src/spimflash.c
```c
/*
MIT License

Copyright (c) 2024 Hurley Research LLC

Permission is hereby granted, free of charge, to any person obtaining a copy
of this software and associated documentation files (the "Software"), to deal
in the Software without restriction, including without limitation the rights
to use, copy, modify, merge, publish, distribute, sublicense, and/or sell
copies of the Software, and to permit persons to whom the Software is
furnished to do so, subject to the following conditions:

The above copyright notice and this permission notice shall be included in all
copies or substantial portions of the Software.

THE SOFTWARE IS PROVIDED "AS IS", WITHOUT WARRANTY OF ANY KIND, EXPRESS OR
IMPLIED, INCLUDING BUT NOT LIMITED TO THE WARRANTIES OF MERCHANTABILITY,
FITNESS FOR A PARTICULAR PURPOSE AND NONINFRINGEMENT. IN NO EVENT SHALL THE
AUTHORS OR COPYRIGHT HOLDERS BE LIABLE FOR ANY CLAIM, DAMAGES OR OTHER
LIABILITY, WHETHER IN AN ACTION OF CONTRACT, TORT OR OTHERWISE, ARISING FROM,
OUT OF OR IN CONNECTION WITH THE SOFTWARE OR THE USE OR OTHER DEALINGS IN THE
SOFTWARE.
 */

#include "spimflash.h"
char str[100];

#define MINX 3
#define MAXX 127
#define MINY 0
#define MAXY 63

uint32_t syncWaiting = 0;

#define TXBUFSIZE 1024

volatile uint8_t flashRxBuf[RXBUFSIZE];

volatile uint8_t flashTxBuf[TXBUFSIZE];
volatile uint8_t returnByte[1];

void writeByte(uint8_t command) {
  flashTxBuf[0] = command;
  flashRxBuf[0] = 0x00;

  NRF_SPIM4_S->TXD.MAXCNT = 1;
  NRF_SPIM4_S->RXD.MAXCNT = 1;

  NRF_SPIM4_S->RXD.PTR = (uint32_t)flashRxBuf;
  NRF_SPIM4_S->TXD.PTR = (uint32_t)flashTxBuf;

  NRF_SPIM4_S->EVENTS_END = 0;

  NRF_SPIM4_S->TASKS_START = 1;
  while (NRF_SPIM4_S->EVENTS_END == 0) {
    syncWaiting++;
  }
}

void flashTestReturn(uint8_t p) {

  uint8_t rv = p + 1;
  returnByte[0] = rv;

}
uint8_t fudgeYou(uint8_t p) {
  uint8_t rv = (uint8_t)(p + 1);
  return rv;
}
uint8_t readByte(uint8_t command) {
  flashTxBuf[0] = command;
  flashRxBuf[0] = 0x00;

  flashRxBuf[1] = 0xff;

  NRF_SPIM4_S->TXD.MAXCNT = 2;
  NRF_SPIM4_S->RXD.MAXCNT = 2;

  NRF_SPIM4_S->RXD.PTR = (uint32_t)flashRxBuf;
  NRF_SPIM4_S->TXD.PTR = (uint32_t)flashTxBuf;

  NRF_SPIM4_S->EVENTS_END = 0;

  NRF_SPIM4_S->TASKS_START = 1;
  while (NRF_SPIM4_S->EVENTS_END == 0) {
    syncWaiting++;
  }
  uint8_t rv = flashRxBuf[1];
  return rv;

}
uint8_t flashReadStatus(void) {
  writeByte(0xab);
  uint8_t rv = readByte(0x05);
  return rv;
}
void flashWriteEnable(void) { writeByte(0x06); }
void flashWriteDisable(void) { writeByte(0x04); }
void flashRead(uint8_t buf[], uint32_t startAddress, uint32_t len) {
  flashTxBuf[0] = 0x03;  // simple serial read
  flashTxBuf[1] = (startAddress >> 16) & 0xff;
  flashTxBuf[2] = (startAddress >> 8) & 0xff;
  flashTxBuf[3] = (startAddress >> 0) & 0xff;

  NRF_SPIM4_S->TXD.MAXCNT = 4;
  NRF_SPIM4_S->RXD.MAXCNT = len + 4;  

  NRF_SPIM4_S->RXD.PTR = (uint32_t)flashRxBuf;
  NRF_SPIM4_S->TXD.PTR = (uint32_t)flashTxBuf;

  NRF_SPIM4_S->EVENTS_END = 0;

  NRF_SPIM4_S->TASKS_START = 1;

  while (NRF_SPIM4_S->EVENTS_END == 0) {
    syncWaiting++;
  }

  for (uint32_t x = 0; x < len; x++) {
    buf[x] = flashRxBuf[x + 4];
  }
}

void flashEraseSector(uint32_t startAddress) {
  flashTxBuf[0] = 0xD8;  
  flashTxBuf[1] = (startAddress >> 16) & 0xff;
  flashTxBuf[2] = (startAddress >> 8) & 0xff;
  flashTxBuf[3] = (startAddress >> 0) & 0xff;

  NRF_SPIM4_S->TXD.MAXCNT = 4;
  NRF_SPIM4_S->RXD.MAXCNT = 4;  

  NRF_SPIM4_S->RXD.PTR = (uint32_t)flashRxBuf;
  NRF_SPIM4_S->TXD.PTR = (uint32_t)flashTxBuf;

  NRF_SPIM4_S->EVENTS_END = 0;

  NRF_SPIM4_S->TASKS_START = 1;
  while (NRF_SPIM4_S->EVENTS_END == 0) {
    syncWaiting++;
  }

 
}

void flashProgram(volatile uint8_t buf[], uint32_t startAddress, uint32_t len) {

  flashTxBuf[0] = 0x02;  // page program, 256 max
  flashTxBuf[1] = (startAddress >> 16) & 0xff;
  flashTxBuf[2] = (startAddress >> 8) & 0xff;
  flashTxBuf[3] = (startAddress >> 0) & 0xff;
  
  for (uint32_t x = 0; x < len; x++) {
    flashTxBuf[x + 4] = buf[x + 4];
  }
  
  NRF_SPIM4_S->TXD.MAXCNT = len + 4;
  NRF_SPIM4_S->RXD.MAXCNT = len + 4;

  NRF_SPIM4_S->RXD.PTR = (uint32_t)flashRxBuf;
  NRF_SPIM4_S->TXD.PTR = (uint32_t)flashTxBuf;

  NRF_SPIM4_S->EVENTS_END = 0;

  NRF_SPIM4_S->TASKS_START = 1;
  while (NRF_SPIM4_S->EVENTS_END == 0) {
    syncWaiting++;
  }
}

void spimFlashInit(void) {
  

  gpioConfigOutputDrive(ICE_SCK, DRIVEH0H1); 
  pinClear(ICE_SCK);
  gpioConfigOutputDrive(ICE_SSB, DRIVEH0H1);  
  pinSet(ICE_SSB);

  gpioConfigOutputDrive(ICE_SDI, DRIVEH0H1);
  pinClear(ICE_SDI);

  gpioConfigInputNoPull(ICE_SDO);
  gpioConfigOutputClear(ICE_CRESETB);
  NRF_SPIM4_S->ENABLE = 0;

  NRF_SPIM4_S->SHORTS = 0;  
  NRF_SPIM4_S->INTENCLR = 0xFFFFFFFF;  
            
  NRF_SPIM4_S->FREQUENCY = 0x02000000;  

  NRF_SPIM4_S->CONFIG = 0x0;  

  NRF_SPIM4_S->PSEL.SCK = ICE_SCK;
  NRF_SPIM4_S->PSEL.CSN = ICE_SSB; 
                                       

  NRF_SPIM4_S->PSEL.MISO = ICE_SDO; 
  NRF_SPIM4_S->PSEL.MOSI = ICE_SDI;
  NRF_SPIM4_S->PSELDCX = 0xffffffff;

  NRF_SPIM4_S->DCXCNT = 0;  
  NRF_SPIM4_S->TXD.MAXCNT = TXBUFSIZE;  
  NRF_SPIM4_S->RXD.MAXCNT = RXBUFSIZE;
  NRF_SPIM4_S->RXD.PTR = (uint32_t)flashRxBuf;
  NRF_SPIM4_S->TXD.PTR = (uint32_t)flashTxBuf;

  NRF_SPIM4_S->ENABLE = 7;
}
```

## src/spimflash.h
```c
/*
MIT License

Copyright (c) 2024 Hurley Research LLC

Permission is hereby granted, free of charge, to any person obtaining a copy
of this software and associated documentation files (the "Software"), to deal
in the Software without restriction, including without limitation the rights
to use, copy, modify, merge, publish, distribute, sublicense, and/or sell
copies of the Software, and to permit persons to whom the Software is
furnished to do so, subject to the following conditions:

The above copyright notice and this permission notice shall be included in all
copies or substantial portions of the Software.

THE SOFTWARE IS PROVIDED "AS IS", WITHOUT WARRANTY OF ANY KIND, EXPRESS OR
IMPLIED, INCLUDING BUT NOT LIMITED TO THE WARRANTIES OF MERCHANTABILITY,
FITNESS FOR A PARTICULAR PURPOSE AND NONINFRINGEMENT. IN NO EVENT SHALL THE
AUTHORS OR COPYRIGHT HOLDERS BE LIABLE FOR ANY CLAIM, DAMAGES OR OTHER
LIABILITY, WHETHER IN AN ACTION OF CONTRACT, TORT OR OTHERWISE, ARISING FROM,
OUT OF OR IN CONNECTION WITH THE SOFTWARE OR THE USE OR OTHER DEALINGS IN THE
SOFTWARE.
 */

#ifndef SOURCEFILESPIMFLASH
#define SOURCEFILESPIMFLASH


 #include "utils.h"
#include <string.h>
#include <stdio.h>
#include <stdint.h>
#define LEFT_JUSTIFY  1
#define RIGHT_JUSTIFY 2




#define RXBUFSIZE 1024
extern volatile uint8_t flashRxBuf[RXBUFSIZE];
extern volatile uint8_t returnByte[1];

void spimFlashInit(void);

void flashRead(uint8_t buf[],uint32_t start, uint32_t len);
uint8_t flashReadStatus(void);
void flashWriteEnable(void);
void flashWriteDisable(void);
void flashEraseSector(uint32_t addr);
void flashProgram(volatile uint8_t buf[],uint32_t startAddress,uint32_t len);
uint8_t fudgeYou(uint8_t p);
void flashTestReturn(uint8_t p);
void readFlashStatus(void);
#endif // SOURCEFILEDISPLAY
```

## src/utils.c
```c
/*
MIT License

Copyright (c) 2024 Hurley Research LLC

Permission is hereby granted, free of charge, to any person obtaining a copy
of this software and associated documentation files (the "Software"), to deal
in the Software without restriction, including without limitation the rights
to use, copy, modify, merge, publish, distribute, sublicense, and/or sell
copies of the Software, and to permit persons to whom the Software is
furnished to do so, subject to the following conditions:

The above copyright notice and this permission notice shall be included in all
copies or substantial portions of the Software.

THE SOFTWARE IS PROVIDED "AS IS", WITHOUT WARRANTY OF ANY KIND, EXPRESS OR
IMPLIED, INCLUDING BUT NOT LIMITED TO THE WARRANTIES OF MERCHANTABILITY,
FITNESS FOR A PARTICULAR PURPOSE AND NONINFRINGEMENT. IN NO EVENT SHALL THE
AUTHORS OR COPYRIGHT HOLDERS BE LIABLE FOR ANY CLAIM, DAMAGES OR OTHER
LIABILITY, WHETHER IN AN ACTION OF CONTRACT, TORT OR OTHERWISE, ARISING FROM,
OUT OF OR IN CONNECTION WITH THE SOFTWARE OR THE USE OR OTHER DEALINGS IN THE
SOFTWARE.
 */

#include "utils.h"

#include <stdio.h>
#include <string.h>

#include <zephyr/kernel.h>

uint8_t uartRxBuffer[COMMSPACKETSIZE];
uint8_t uartTxBuffer[COMMSPACKETSIZE];

void lgv(char msg[], uint8_t val)
{

    if (NRF_UARTE2_S->EVENTS_ENDTX == 0)
    {
    
      k_sleep(K_MSEC(1));
    }

  for (uint8_t x = 0; x < COMMSPACKETSIZE; x++)
  {
    uartTxBuffer[x] = 32;
  }
  NRF_UARTE2_S->EVENTS_ENDTX = 0;
  sprintf(uartTxBuffer, msg, val);

  uartTxBuffer[32] = 13;
  uartTxBuffer[33] = 13;
  NRF_UARTE2_S->TXD.MAXCNT = 34;
  NRF_UARTE2_S->TASKS_STARTTX = 1;
}
void lg(char msg[])
{

    if (NRF_UARTE2_S->EVENTS_ENDTX == 0)
    {
        k_sleep(K_MSEC(1));
    }

  for (uint8_t x = 0; x < COMMSPACKETSIZE; x++)
  {
    uartTxBuffer[x] = 32;
  }
  NRF_UARTE2_S->EVENTS_ENDTX = 0;
  int l = strlen(msg);

  for (uint32_t x = 0; x < l; x++)
  {
    uartTxBuffer[x] = msg[x];
  }

  uartTxBuffer[32] = 13;

  uartTxBuffer[33] = 13;

  NRF_UARTE2_S->TXD.MAXCNT = 34;

  NRF_UARTE2_S->TASKS_STARTTX = 1;

}

void setupSeggerUART(void)
{

  gpioConfigOutputSet(NRF_TXD);
  gpioConfigInputNoPull(NRF_RXD);
  gpioConfigOutputSet(NRF_RTS);
  gpioConfigInputNoPull(NRF_CTS);


  NRF_UARTE2_S->ENABLE = UARTE_ENABLE_ENABLE_Disabled;

  NRF_UARTE2_S->CONFIG = 1; // one stop bit, no parity, hfc enabled

  NRF_UARTE2_S->BAUDRATE = UARTE_BAUDRATE_BAUDRATE_Baud115200; 
  NRF_UARTE2_S->PSEL.TXD = NRF_TXD;                           
  NRF_UARTE2_S->PSEL.RXD = NRF_RXD;                         

  NRF_UARTE2_S->PSEL.CTS = NRF_CTS; 
  NRF_UARTE2_S->PSEL.RTS = NRF_RTS; 

  NRF_UARTE2_S->RXD.MAXCNT = COMMSPACKETSIZE;
  NRF_UARTE2_S->RXD.PTR = (uint32_t)uartRxBuffer;
  NRF_UARTE2_S->TXD.MAXCNT = COMMSPACKETSIZE;
  NRF_UARTE2_S->TXD.PTR = (uint32_t)uartTxBuffer;
  NRF_UARTE2_S->ENABLE = UARTE_ENABLE_ENABLE_Enabled;
  NRF_UARTE2_S->INTENSET = 0x0; // no interrupts
  NRF_UARTE2_S->SHORTS = 0x0;

  /*
  NVIC_ClearPendingIRQ(SPIM2_SPIS2_TWIM2_TWIS2_UARTE2_IRQn);
  NVIC_SetPriority(SPIM2_SPIS2_TWIM2_TWIS2_UARTE2_IRQn, 3);
  NVIC_EnableIRQ(SPIM2_SPIS2_TWIM2_TWIS2_UARTE2_IRQn);
  */

  // NRF_UARTE2_S->TASKS_STARTRX = 1;
}

uint8_t randomBytes[256] = {148, 48, 140, 166, 127, 162, 217, 64, 114, 71, 74, 168, 51, 151, 19, 53, 34, 40, 57, 99, 66, 49, 61, 161, 205, 92, 39, 107,
                            52, 55, 184, 65, 226, 230, 173, 119, 117, 46, 213, 163, 96, 62, 123, 191, 207, 142, 202, 149, 229, 176, 112, 132, 94, 198, 103, 200, 76, 185, 136, 252, 236,
                            138, 156, 159, 84, 250, 43, 30, 141, 4, 56, 221, 118, 9, 139, 21, 164, 235, 247, 109, 47, 73, 174, 68, 27, 177, 95, 232, 36, 70, 80, 175, 170, 6, 98, 211,
                            182, 106, 104, 158, 97, 131, 189, 126, 150, 209, 101, 5, 147, 190, 178, 20, 160, 2, 29, 194, 67, 44, 89, 1, 255, 239, 11, 59, 130, 248, 204, 87, 110, 180,
                            113, 37, 28, 125, 42, 249, 105, 201, 144, 171, 75, 220, 187, 82, 242, 233, 63, 244, 79, 23, 129, 183, 215, 192, 186, 10, 254, 22, 181, 41, 81, 88, 8, 16,
                            157, 219, 54, 83, 223, 122, 7, 179, 237, 165, 169, 14, 152, 31, 234, 253, 246, 214, 58, 86, 32, 33, 102, 216, 18, 111, 77, 78, 25, 26, 12, 228, 100, 172,
                            243, 208, 69, 199, 120, 238, 225, 72, 245, 116, 167, 3, 155, 206, 108, 134, 50, 188, 13, 0, 203, 17, 212, 197, 24, 15, 195, 45, 251, 227, 60, 135, 222,
                            128, 193, 93, 143, 196, 85, 133, 224, 90, 210, 145, 121, 231, 241, 137, 35, 91, 124, 38, 115, 154, 146, 240, 218, 153};

uint8_t randomByteIndex = 0;
uint8_t randomByte(void)
{
  randomByteIndex++;
  if (randomByteIndex > 255)
  {
    randomByteIndex = 0;
  }

  return randomBytes[randomByteIndex];
}
uint32_t randomUInt32(void)
{
  uint32_t out = randomByte();
  out += randomByte() << 8;
  out += randomByte() << 16;
  out += randomByte() << 24;
  return out;
}
float randomFloat(float lessThan)
{
  return (((float)randomByte()) * lessThan) / 256.0f;
}
uint8_t randomUInt8(uint8_t lessThan)
{
  return (uint8_t)randomFloat((float)lessThan);
}
void pack32(uint32_t x, uint8_t data[], uint32_t loc)
{
  data[loc + 3] = (x >> 24) & 0xff;
  data[loc + 2] = (x >> 16) & 0xff;
  data[loc + 1] = (x >> 8) & 0xff;
  data[loc] = x & 0xff;
}
void pack24(uint32_t x, uint8_t data[], uint32_t loc)
{
  // data[loc + 3] = (x >> 24) & 0xff;
  data[loc + 2] = (x >> 16) & 0xff;
  data[loc + 1] = (x >> 8) & 0xff;
  data[loc] = x & 0xff;
}
uint32_t unpack32(uint8_t data[], uint32_t loc)
{
  uint32_t rv = 0x00000000;
  rv += (data[loc + 3] << 24) & 0xff000000;
  rv += (data[loc + 2] << 16) & 0x00ff0000;
  rv += (data[loc + 1] << 8) & 0x0000ff00;
  rv += data[loc] & 0x000000ff;
  return rv;
}
int32_t unpack24(uint8_t data[], uint32_t loc)
{
  int32_t rv = 0x00000000;
  // rv += (data[loc + 3] << 24) & 0xff000000;
  rv += (data[loc + 2] << 16) & 0x00ff0000;
  rv += (data[loc + 1] << 8) & 0x0000ff00;
  rv += data[loc] & 0x000000ff;
  if (rv & 0x00800000)
  {
    rv = rv & 0x007fffff;
    rv = rv * -1;
    // rv = rv | 0x80000000;
  }
  return rv; // but.. we really want to propagate sign as well? fuck. lets see what comes in.
}
void pack16(uint16_t val, uint8_t *array, uint32_t index)
{
  array[index + 1] = (val >> 8) & 0xff;
  array[index] = val & 0xff;
}
uint16_t unpack16(uint8_t data[], uint32_t loc)
{
  uint16_t rv = 0x0000;
  rv += (data[loc + 1] << 8) & 0xff00;
  rv += data[loc] & 0x00ff;
  return rv;
}
void packFloat(float x, uint8_t *data, uint32_t loc)
{
  uint8_t is_negative = 0;
  float local_x = x;
  int32_t exponent = 0;
  if (local_x < 0)
  {
    local_x = -local_x;
    is_negative = 1;
  }
  if (local_x != 0.0f)
  {
    while (local_x >= 1000000.0f)
    {
      local_x /= 10.0f;
      exponent++;
    }
    while (local_x < 100000.0f)
    {
      local_x *= 10.0f;
      exponent--;
    }
  }
  int32_t mantissa = (int32_t)local_x;
  if (is_negative == 1)
  {
    mantissa = -mantissa;
  }
  uint32_t packed32 = (mantissa & 0x00ffffff) | ((exponent << 24) & 0xff000000);
  pack32(packed32, data, loc);
}

float unpackFloat(uint8_t source[], uint32_t loc)
{
  int8_t exponent = source[loc + 3];
  // int8_t exponent = (int8_t)*dst++;
  int32_t mantissa = 0;
  for (int i = 0; i < 3; i++)
  {
    mantissa = 256 * mantissa + source[loc + 2 - i];
  }
  if (mantissa & 0x00800000)
    mantissa |= 0xff000000; //  Sign Extend
  float v = mantissa;
  while (exponent > 0)
  {
    v *= 10.0f;
    exponent--;
  }
  while (exponent < 0)
  {
    v /= 10.0f;
    exponent++;
  }
  return v;
}

void gpioConfigGeneral(uint8_t pn, uint8_t io, uint8_t inputConnect, uint8_t pull,
                       uint8_t drive, uint8_t sense, uint8_t mcusel)
{
  uint32_t c = 0x00000000;
  c += io;
  c += inputConnect << 1;
  c += pull << 2;
  c += drive << 8;
  c += sense << 16;
  c += mcusel << 28;

  if (pn < 32)
  {
    NRF_P0_S->PIN_CNF[pn] = c;
  }
  else
  {
    NRF_P1_S->PIN_CNF[pn - 32] = c;
  }
}
void gpioConfigOutputDrive(uint8_t pn, uint8_t drive)
{
  gpioConfigGeneral(pn, IOOUTPUT, ICDISCONNECT, PULLNOPULL, drive, SENSEDISABLE, MCUSELAPP);
}
void gpioConfigInput(uint8_t pn, uint8_t pull)
{
  gpioConfigGeneral(pn, IOINPUT, ICCONNECT, pull, DRIVES0S1, SENSEDISABLE, MCUSELAPP);
}

void pinClear(uint8_t pin)
{
  if (pin < 32)
  {
    NRF_P0_S->OUTCLR = 1 << pin;
  }
  else
  {
    NRF_P1_S->OUTCLR = 1 << (pin - 32);
  }
}
void pinSet(uint8_t pin)
{
  if (pin < 32)
  {
    NRF_P0_S->OUTSET = 1 << pin;
  }
  else
  {
    NRF_P1_S->OUTSET = 1 << (pin - 32);
  }
}

void gpioConfigOutput(uint32_t pn)
{
  gpioConfigGeneral(pn, IOOUTPUT, ICDISCONNECT, PULLNOPULL, DRIVES0S1, SENSEDISABLE, MCUSELAPP);
  /* if (pn < 32) {
    NRF_P0_S->PIN_CNF[pn] = 0x00000003;
  } else {
    NRF_P1_S->PIN_CNF[pn - 32] = 0x00000003;
  }*/
}

void gpioConfigOutputClear(uint32_t pn)
{
  gpioConfigOutput(pn);
  pinClear(pn);
}
void gpioConfigOutputSet(uint32_t pn)
{
  gpioConfigOutput(pn);
  pinSet(pn);
}

void gpioConfigInputDisconnect(uint32_t pn)
{
  gpioConfigGeneral(pn, IOINPUT, ICDISCONNECT, PULLNOPULL, DRIVES0S1, SENSEDISABLE, MCUSELAPP);
}
void gpioConfigInputNoPull(uint32_t pn)
{
  gpioConfigInput(pn, PULLNOPULL);
}

uint8_t gpioPinRead(uint32_t pn)
{
  if (pn < 32)
  {
    if (NRF_P0_S->IN & (1 << pn))
    {
      return 1;
    }
    return 0;
  }
  else
  {
    if (NRF_P1_S->IN & (1 << (pn - 32)))
    {
      return 1;
    }
    return 0;
  }
}
```
